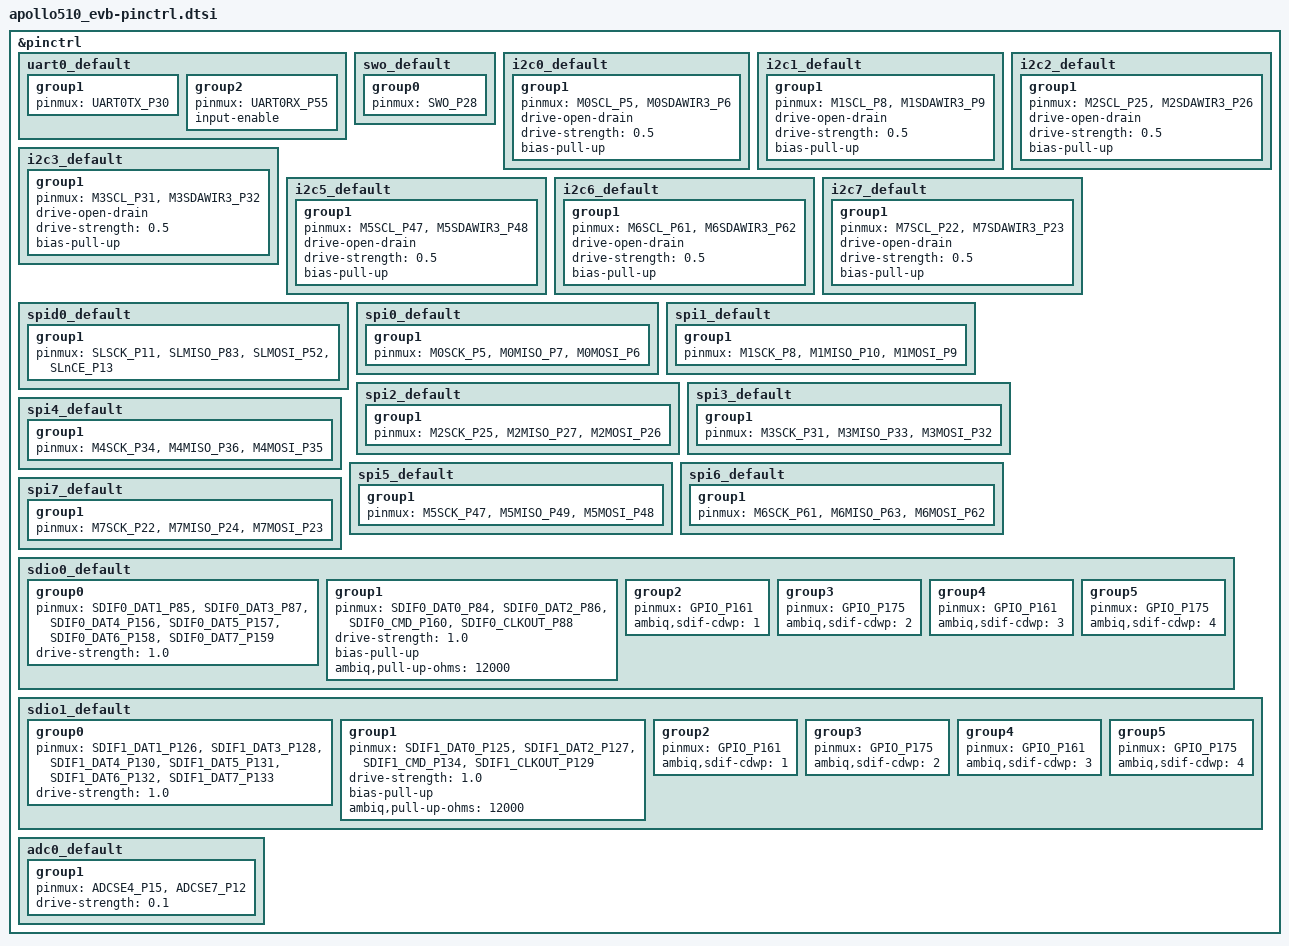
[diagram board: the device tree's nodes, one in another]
/*
 * Copyright (c) 2025 Ambiq Micro Inc.
 *
 * SPDX-License-Identifier: Apache-2.0
 */

#include <apollo510/ambiq-apollo510-pinmux.h>

&pinctrl {
	uart0_default: uart0_default {
		group1 {
			pinmux = <UART0TX_P30>;
		};
		group2 {
			pinmux = <UART0RX_P55>;
			input-enable;
		};
	};
	swo_default: swo_default {
		group0 {
			pinmux = <SWO_P28>;
		};
	};
	i2c0_default: i2c0_default {
		group1 {
			pinmux = <M0SCL_P5>, <M0SDAWIR3_P6>;
			drive-open-drain;
			drive-strength = "0.5";
			bias-pull-up;
		};
	};
	i2c1_default: i2c1_default {
		group1 {
			pinmux = <M1SCL_P8>, <M1SDAWIR3_P9>;
			drive-open-drain;
			drive-strength = "0.5";
			bias-pull-up;
		};
	};
	i2c2_default: i2c2_default {
		group1 {
			pinmux = <M2SCL_P25>, <M2SDAWIR3_P26>;
			drive-open-drain;
			drive-strength = "0.5";
			bias-pull-up;
		};
	};
	i2c3_default: i2c3_default {
		group1 {
			pinmux = <M3SCL_P31>, <M3SDAWIR3_P32>;
			drive-open-drain;
			drive-strength = "0.5";
			bias-pull-up;
		};
	};
	i2c5_default: i2c5_default {
		group1 {
			pinmux = <M5SCL_P47>, <M5SDAWIR3_P48>;
			drive-open-drain;
			drive-strength = "0.5";
			bias-pull-up;
		};
	};
	i2c6_default: i2c6_default {
		group1 {
			pinmux = <M6SCL_P61>, <M6SDAWIR3_P62>;
			drive-open-drain;
			drive-strength = "0.5";
			bias-pull-up;
		};
	};
	i2c7_default: i2c7_default {
		group1 {
			pinmux = <M7SCL_P22>, <M7SDAWIR3_P23>;
			drive-open-drain;
			drive-strength = "0.5";
			bias-pull-up;
		};
	};
	spid0_default: spid0_default {
		group1 {
			pinmux = <SLSCK_P11>, <SLMISO_P83>, <SLMOSI_P52>, <SLnCE_P13>;
		};
	};
	spi0_default: spi0_default {
		group1 {
			pinmux = <M0SCK_P5>, <M0MISO_P7>, <M0MOSI_P6>;
		};
	};
	spi1_default: spi1_default {
		group1 {
			pinmux = <M1SCK_P8>, <M1MISO_P10>, <M1MOSI_P9>;
		};
	};
	spi2_default: spi2_default {
		group1 {
			pinmux = <M2SCK_P25>, <M2MISO_P27>, <M2MOSI_P26>;
		};
	};
	spi3_default: spi3_default {
		group1 {
			pinmux = <M3SCK_P31>, <M3MISO_P33>, <M3MOSI_P32>;
		};
	};
	spi4_default: spi4_default {
		group1 {
			pinmux = <M4SCK_P34>, <M4MISO_P36>, <M4MOSI_P35>;
		};
	};
	spi5_default: spi5_default {
		group1 {
			pinmux = <M5SCK_P47>, <M5MISO_P49>, <M5MOSI_P48>;
		};
	};
	spi6_default: spi6_default {
		group1 {
			pinmux = <M6SCK_P61>, <M6MISO_P63>, <M6MOSI_P62>;
		};
	};
	spi7_default: spi7_default {
		group1 {
			pinmux = <M7SCK_P22>, <M7MISO_P24>, <M7MOSI_P23>;
		};
	};
	sdio0_default: sdio0_default {
		group0 {
			pinmux = <SDIF0_DAT1_P85>,
				 <SDIF0_DAT3_P87>,
				 <SDIF0_DAT4_P156>,
				 <SDIF0_DAT5_P157>,
				 <SDIF0_DAT6_P158>,
				 <SDIF0_DAT7_P159>;
				 drive-strength = "1.0";
		};
		group1 {
			pinmux =
				 <SDIF0_DAT0_P84>,
				 <SDIF0_DAT2_P86>,
				 <SDIF0_CMD_P160>,
				 <SDIF0_CLKOUT_P88>;
				 drive-strength = "1.0";
				 bias-pull-up;
				 ambiq,pull-up-ohms = <12000>;
		};
		group2 {
			pinmux = <GPIO_P161>;
				 ambiq,sdif-cdwp = <1>;
		};
		group3 {
			pinmux = <GPIO_P175>;
				 ambiq,sdif-cdwp = <2>;
		};
		group4 {
			pinmux = <GPIO_P161>;
				 ambiq,sdif-cdwp = <3>;
		};
		group5 {
			pinmux = <GPIO_P175>;
				 ambiq,sdif-cdwp = <4>;
		};
	};
	sdio1_default: sdio1_default {
		group0 {
			pinmux = <SDIF1_DAT1_P126>,
				 <SDIF1_DAT3_P128>,
				 <SDIF1_DAT4_P130>,
				 <SDIF1_DAT5_P131>,
				 <SDIF1_DAT6_P132>,
				 <SDIF1_DAT7_P133>;
				 drive-strength = "1.0";
		};
		group1 {
			pinmux = <SDIF1_DAT0_P125>,
				 <SDIF1_DAT2_P127>,
				 <SDIF1_CMD_P134>,
				 <SDIF1_CLKOUT_P129>;
				 drive-strength = "1.0";
				 bias-pull-up;
				 ambiq,pull-up-ohms = <12000>;
		};
		group2 {
			pinmux = <GPIO_P161>;
				 ambiq,sdif-cdwp = <1>;
		};
		group3 {
			pinmux = <GPIO_P175>;
				 ambiq,sdif-cdwp = <2>;
		};
		group4 {
			pinmux = <GPIO_P161>;
				 ambiq,sdif-cdwp = <3>;
		};
		group5 {
			pinmux = <GPIO_P175>;
				 ambiq,sdif-cdwp = <4>;
		};
	};
	adc0_default: adc0_default{
		group1 {
			pinmux = <ADCSE4_P15>, <ADCSE7_P12>;
			drive-strength = "0.1";
		};
	};
};
